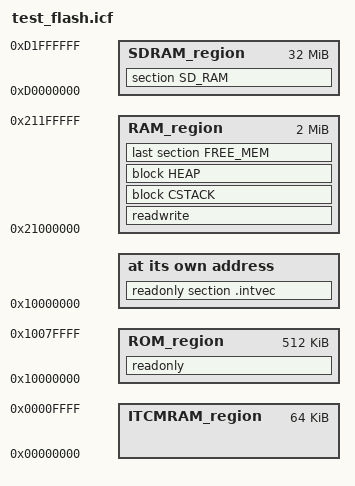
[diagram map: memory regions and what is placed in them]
/*###ICF### Section handled by ICF editor, don't touch! ****/
/*-Editor annotation file-*/
/* IcfEditorFile="$TOOLKIT_DIR$\config\ide\IcfEditor\cortex_v1_0.xml" */
/*-Specials-*/
define symbol __ICFEDIT_intvec_start__ = 0x10000000;
/*-Memory Regions-*/
define symbol __ICFEDIT_region_ROM_start__     = 0x10000000;
define symbol __ICFEDIT_region_ROM_end__       = 0x1007FFFF;
define symbol __ICFEDIT_region_RAM_start__     = 0x21000000;
define symbol __ICFEDIT_region_RAM_end__       = 0x211FFFFF;
define symbol __ICFEDIT_region_ITCMRAM_start__ = 0x00000000;
define symbol __ICFEDIT_region_ITCMRAM_end__   = 0x0000FFFF;
/*-Sizes-*/
define symbol __ICFEDIT_size_cstack__ = 0x500;
define symbol __ICFEDIT_size_heap__   = 0x41000;
/**** End of ICF editor section. ###ICF###*/

define symbol __SDRAM_start__ = 0xD0000000;
define symbol __SDRAM_end__   = 0xD1FFFFFF;


define memory mem with size = 4G;
define region ROM_region      = mem:[from __ICFEDIT_region_ROM_start__   to __ICFEDIT_region_ROM_end__];
define region RAM_region      = mem:[from __ICFEDIT_region_RAM_start__   to __ICFEDIT_region_RAM_end__];
define region ITCMRAM_region  = mem:[from __ICFEDIT_region_ITCMRAM_start__ to __ICFEDIT_region_ITCMRAM_end__];
define region SDRAM_region    = mem:[from __SDRAM_start__   to __SDRAM_end__];

define block CSTACK    with alignment = 8, size = __ICFEDIT_size_cstack__   { };
define block HEAP      with alignment = 8, size = __ICFEDIT_size_heap__     { };

initialize by copy { readwrite };
do not initialize  { section .noinit };

place at address mem:__ICFEDIT_intvec_start__ { readonly section .intvec };

place in ROM_region   { readonly };
place in RAM_region   { readwrite,
                        block CSTACK, block HEAP };
place in SDRAM_region  { section SD_RAM };
place in RAM_region    { last section FREE_MEM};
